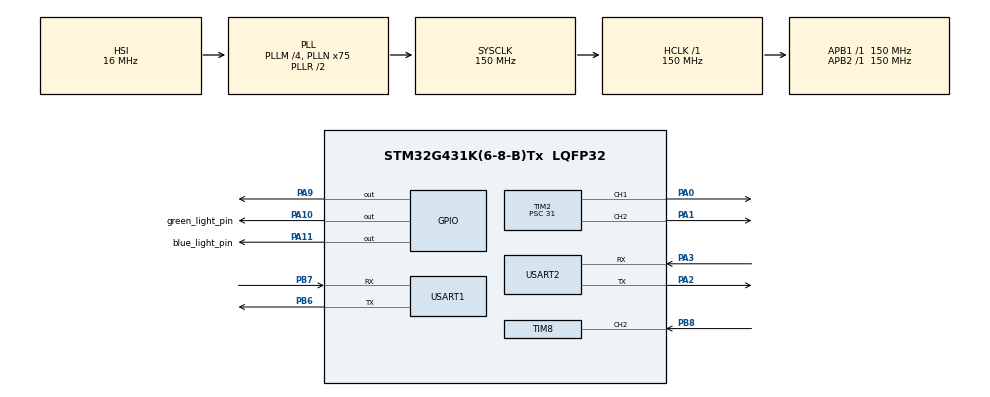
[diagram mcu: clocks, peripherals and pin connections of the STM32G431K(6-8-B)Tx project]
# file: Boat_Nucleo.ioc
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Dma.Request0=USART1_RX
Dma.Request1=USART1_TX
Dma.USART1_RX.0.Direction=DMA_PERIPH_TO_MEMORY
Dma.USART1_RX.0.EventEnable=DISABLE
Dma.USART1_RX.0.Instance=DMA1_Channel1
Dma.USART1_RX.0.MemDataAlignment=DMA_MDATAALIGN_BYTE
Dma.USART1_RX.0.MemInc=DMA_MINC_ENABLE
Dma.USART1_RX.0.Mode=DMA_NORMAL
Dma.USART1_RX.0.PeriphDataAlignment=DMA_PDATAALIGN_BYTE
Dma.USART1_RX.0.PeriphInc=DMA_PINC_DISABLE
Dma.USART1_RX.0.Polarity=HAL_DMAMUX_REQ_GEN_RISING
Dma.USART1_RX.0.Priority=DMA_PRIORITY_LOW
Dma.USART1_RX.0.RequestNumber=1
Dma.USART1_RX.0.SignalID=NONE
Dma.USART1_RX.0.SyncEnable=DISABLE
Dma.USART1_RX.0.SyncPolarity=HAL_DMAMUX_SYNC_NO_EVENT
Dma.USART1_RX.0.SyncRequestNumber=1
Dma.USART1_RX.0.SyncSignalID=NONE
Dma.USART1_TX.1.Direction=DMA_MEMORY_TO_PERIPH
Dma.USART1_TX.1.EventEnable=DISABLE
Dma.USART1_TX.1.Instance=DMA1_Channel2
Dma.USART1_TX.1.MemDataAlignment=DMA_MDATAALIGN_BYTE
Dma.USART1_TX.1.MemInc=DMA_MINC_ENABLE
Dma.USART1_TX.1.Mode=DMA_NORMAL
Dma.USART1_TX.1.PeriphDataAlignment=DMA_PDATAALIGN_BYTE
Dma.USART1_TX.1.PeriphInc=DMA_PINC_DISABLE
Dma.USART1_TX.1.Polarity=HAL_DMAMUX_REQ_GEN_RISING
Dma.USART1_TX.1.Priority=DMA_PRIORITY_LOW
Dma.USART1_TX.1.RequestNumber=1
Dma.USART1_TX.1.SignalID=NONE
Dma.USART1_TX.1.SyncEnable=DISABLE
Dma.USART1_TX.1.SyncPolarity=HAL_DMAMUX_SYNC_NO_EVENT
Dma.USART1_TX.1.SyncRequestNumber=1
Dma.USART1_TX.1.SyncSignalID=NONE
FREERTOS.Tasks01=idle_task,8,128,idle_task_update,Default,NULL,Dynamic,NULL,NULL;main_task,24,1024,main_task_thread,Default,NULL,Dynamic,NULL,NULL
FREERTOS.configCHECK_FOR_STACK_OVERFLOW=1
FREERTOS.configENABLE_FPU=1
FREERTOS.configIDLE_SHOULD_YIELD=1
FREERTOS.configTICK_RATE_HZ=250
FREERTOS.configTOTAL_HEAP_SIZE=8192
FREERTOS.configUSE_DAEMON_TASK_STARTUP_HOOK=0
FREERTOS.configUSE_IDLE_HOOK=0
FREERTOS.configUSE_MALLOC_FAILED_HOOK=0
FREERTOS.configUSE_PREEMPTION=0
FREERTOS.configUSE_TICKLESS_IDLE=0
FREERTOS.configUSE_TICK_HOOK=0
Mcu.Family=STM32G4
Mcu.Name=STM32G431K(6-8-B)Tx
Mcu.Package=LQFP32
NVIC.DMA1_Channel1_IRQn=true\:5\:0\:false\:false\:true\:true\:false\:true
NVIC.DMA1_Channel2_IRQn=true\:5\:0\:false\:false\:true\:true\:false\:true
NVIC.PriorityGroup=NVIC_PRIORITYGROUP_4
NVIC.TIM1_TRG_COM_TIM17_IRQn=true\:0\:0\:false\:false\:true\:false\:false\:true
NVIC.TimeBase=TIM1_TRG_COM_TIM17_IRQn
NVIC.TimeBaseIP=TIM17
PA0.Signal=S_TIM2_CH1
PA1.Signal=S_TIM2_CH2
PA10.GPIO_Label=green_light_pin
PA10.Signal=GPIO_Output
PA11.GPIO_Label=blue_light_pin
PA11.Signal=GPIO_Output
PA13.Mode=Serial_Wire
PA13.Signal=SYS_JTMS-SWDIO
PA14.Mode=Serial_Wire
PA14.Signal=SYS_JTCK-SWCLK
PA2.Mode=Asynchronous
PA2.Signal=USART2_TX
PA3.Mode=Asynchronous
PA3.Signal=USART2_RX
PA9.Signal=GPIO_Output
PB6.Mode=Asynchronous
PB6.Signal=USART1_TX
PB7.Mode=Asynchronous
PB7.Signal=USART1_RX
PB8-BOOT0.Signal=S_TIM8_CH2
ProjectManager.HeapSize=0x200
ProjectManager.StackSize=0x400
ProjectManager.TargetToolchain=STM32CubeIDE
RCC.ADC12Freq_Value=150000000
RCC.AHBFreq_Value=150000000
RCC.APB1Freq_Value=150000000
RCC.APB1TimFreq_Value=150000000
RCC.APB2Freq_Value=150000000
RCC.APB2TimFreq_Value=150000000
RCC.CortexFreq_Value=150000000
RCC.EXTERNAL_CLOCK_VALUE=12288000
RCC.HCLKFreq_Value=150000000
RCC.HSE_VALUE=8000000
RCC.HSI48_VALUE=48000000
RCC.HSI_VALUE=16000000
RCC.LSE_VALUE=32768
RCC.PLLM=RCC_PLLM_DIV4
RCC.PLLN=75
RCC.SYSCLKFreq_VALUE=150000000
RCC.SYSCLKSource=RCC_SYSCLKSOURCE_PLLCLK
RCC.USBFreq_Value=150000000
RCC.VCOOutputFreq_Value=300000000
SH.S_TIM2_CH1.0=TIM2_CH1,PWM Generation1 CH1
SH.S_TIM2_CH2.0=TIM2_CH2,PWM Generation2 CH2
SH.S_TIM8_CH2.0=TIM8_CH2,Input_Capture2_from_TI2
TIM2.AutoReloadPreload=TIM_AUTORELOAD_PRELOAD_ENABLE
TIM2.Channel-PWM\ Generation1\ CH1=TIM_CHANNEL_1
TIM2.Channel-PWM\ Generation2\ CH2=TIM_CHANNEL_2
TIM2.PeriodNoDither=100000
TIM2.Prescaler=31
TIM2.PulseNoDither_1=0
TIM2.PulseNoDither_2=0
TIM8.Channel-Input_Capture2_from_TI2=TIM_CHANNEL_2
USART1.VirtualMode-Asynchronous=VM_ASYNC
USART2.AutoBaudRateEnableParam=UART_ADVFEATURE_AUTOBAUDRATE_DISABLE
USART2.VirtualMode-Asynchronous=VM_ASYNC
VP_FREERTOS_VS_CMSIS_V2.Mode=CMSIS_V2
VP_SYS_VS_DBSignals.Mode=DisableDeadBatterySignals
VP_SYS_VS_tim17.Mode=TIM17
VP_TIM2_VS_ClockSourceINT.Mode=Internal
board=custom

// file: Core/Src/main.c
/* USER CODE BEGIN Header */
/**
  ******************************************************************************
  * @file           : main.c
  * @brief          : Main program body
  ******************************************************************************
  * @attention
  *
  * <h2><center>&copy; Copyright (c) 2020 STMicroelectronics.
  * All rights reserved.</center></h2>
  *
  * This software component is licensed by ST under Ultimate Liberty license
  * SLA0044, the "License"; You may not use this file except in compliance with
  * the License. You may obtain a copy of the License at:
  *                             www.st.com/SLA0044
  *
  ******************************************************************************
  */
/* USER CODE END Header */
#include "main.h"
#include "cmsis_os.h"

/* USER CODE BEGIN Includes */
#include "main_task.h"
/* USER CODE END Includes */

TIM_HandleTypeDef htim2;
TIM_HandleTypeDef htim8;

UART_HandleTypeDef huart1;
UART_HandleTypeDef huart2;
DMA_HandleTypeDef hdma_usart1_rx;
DMA_HandleTypeDef hdma_usart1_tx;

/* Definitions for idle_task */
osThreadId_t idle_taskHandle;
const osThreadAttr_t idle_task_attributes = {
  .name = "idle_task",
  .priority = (osPriority_t) osPriorityLow,
  .stack_size = 128 * 4
};
/* Definitions for main_task */
osThreadId_t main_taskHandle;
const osThreadAttr_t main_task_attributes = {
  .name = "main_task",
  .priority = (osPriority_t) osPriorityNormal,
  .stack_size = 1024 * 4
};

void SystemClock_Config(void);
static void MX_GPIO_Init(void);
static void MX_DMA_Init(void);
static void MX_TIM8_Init(void);
static void MX_USART2_UART_Init(void);
static void MX_TIM2_Init(void);
static void MX_USART1_UART_Init(void);
void idle_task_update(void *argument);
void main_task_thread(void *argument);

int main(void)
{

  /* MCU Configuration--------------------------------------------------------*/

  /* Reset of all peripherals, Initializes the Flash interface and the Systick. */
  HAL_Init();

  /* Configure the system clock */
  SystemClock_Config();

  /* Initialize all configured peripherals */
  MX_GPIO_Init();
  MX_DMA_Init();
  MX_TIM8_Init();
  MX_USART2_UART_Init();
  MX_TIM2_Init();
  MX_USART1_UART_Init();

  /* Init scheduler */
  osKernelInitialize();

  /* Create the thread(s) */
  /* creation of idle_task */
  idle_taskHandle = osThreadNew(idle_task_update, NULL, &idle_task_attributes);

  /* creation of main_task */
  main_taskHandle = osThreadNew(main_task_thread, NULL, &main_task_attributes);

  /* USER CODE BEGIN RTOS_THREADS */
  configASSERT(main_taskHandle != 0);
  /* add threads, ... */
  /* USER CODE END RTOS_THREADS */

  /* Start scheduler */
  osKernelStart();

  /* We should never get here as control is now taken by the scheduler */
  /* Infinite loop */
  while (1)
  {

  }
}

void SystemClock_Config(void)
{
  RCC_OscInitTypeDef RCC_OscInitStruct = {0};
  RCC_ClkInitTypeDef RCC_ClkInitStruct = {0};
  RCC_PeriphCLKInitTypeDef PeriphClkInit = {0};

  /** Configure the main internal regulator output voltage
  */
  HAL_PWREx_ControlVoltageScaling(PWR_REGULATOR_VOLTAGE_SCALE1);
  /** Initializes the RCC Oscillators according to the specified parameters
  * in the RCC_OscInitTypeDef structure.
  */
  RCC_OscInitStruct.OscillatorType = RCC_OSCILLATORTYPE_HSI;
  RCC_OscInitStruct.HSIState = RCC_HSI_ON;
  RCC_OscInitStruct.HSICalibrationValue = RCC_HSICALIBRATION_DEFAULT;
  RCC_OscInitStruct.PLL.PLLState = RCC_PLL_ON;
  RCC_OscInitStruct.PLL.PLLSource = RCC_PLLSOURCE_HSI;
  RCC_OscInitStruct.PLL.PLLM = RCC_PLLM_DIV4;
  RCC_OscInitStruct.PLL.PLLN = 75;
  RCC_OscInitStruct.PLL.PLLP = RCC_PLLP_DIV2;
  RCC_OscInitStruct.PLL.PLLQ = RCC_PLLQ_DIV2;
  RCC_OscInitStruct.PLL.PLLR = RCC_PLLR_DIV2;
  if (HAL_RCC_OscConfig(&RCC_OscInitStruct) != HAL_OK)
  {
    Error_Handler();
  }
  /** Initializes the CPU, AHB and APB buses clocks
  */
  RCC_ClkInitStruct.ClockType = RCC_CLOCKTYPE_HCLK|RCC_CLOCKTYPE_SYSCLK
                              |RCC_CLOCKTYPE_PCLK1|RCC_CLOCKTYPE_PCLK2;
  RCC_ClkInitStruct.SYSCLKSource = RCC_SYSCLKSOURCE_PLLCLK;
  RCC_ClkInitStruct.AHBCLKDivider = RCC_SYSCLK_DIV1;
  RCC_ClkInitStruct.APB1CLKDivider = RCC_HCLK_DIV1;
  RCC_ClkInitStruct.APB2CLKDivider = RCC_HCLK_DIV1;

  if (HAL_RCC_ClockConfig(&RCC_ClkInitStruct, FLASH_LATENCY_4) != HAL_OK)
  {
    Error_Handler();
  }
  /** Initializes the peripherals clocks
  */
  PeriphClkInit.PeriphClockSelection = RCC_PERIPHCLK_USART1|RCC_PERIPHCLK_USART2;
  PeriphClkInit.Usart1ClockSelection = RCC_USART1CLKSOURCE_PCLK2;
  PeriphClkInit.Usart2ClockSelection = RCC_USART2CLKSOURCE_PCLK1;
  if (HAL_RCCEx_PeriphCLKConfig(&PeriphClkInit) != HAL_OK)
  {
    Error_Handler();
  }
}

static void MX_TIM2_Init(void)
{

  TIM_ClockConfigTypeDef sClockSourceConfig = {0};
  TIM_MasterConfigTypeDef sMasterConfig = {0};
  TIM_OC_InitTypeDef sConfigOC = {0};

  htim2.Instance = TIM2;
  htim2.Init.Prescaler = 31;
  htim2.Init.CounterMode = TIM_COUNTERMODE_UP;
  htim2.Init.Period = 100000;
  htim2.Init.ClockDivision = TIM_CLOCKDIVISION_DIV1;
  htim2.Init.AutoReloadPreload = TIM_AUTORELOAD_PRELOAD_ENABLE;
  if (HAL_TIM_Base_Init(&htim2) != HAL_OK)
  {
    Error_Handler();
  }
  sClockSourceConfig.ClockSource = TIM_CLOCKSOURCE_INTERNAL;
  if (HAL_TIM_ConfigClockSource(&htim2, &sClockSourceConfig) != HAL_OK)
  {
    Error_Handler();
  }
  if (HAL_TIM_PWM_Init(&htim2) != HAL_OK)
  {
    Error_Handler();
  }
  sMasterConfig.MasterOutputTrigger = TIM_TRGO_RESET;
  sMasterConfig.MasterSlaveMode = TIM_MASTERSLAVEMODE_DISABLE;
  if (HAL_TIMEx_MasterConfigSynchronization(&htim2, &sMasterConfig) != HAL_OK)
  {
    Error_Handler();
  }
  sConfigOC.OCMode = TIM_OCMODE_PWM1;
  sConfigOC.Pulse = 0;
  sConfigOC.OCPolarity = TIM_OCPOLARITY_HIGH;
  sConfigOC.OCFastMode = TIM_OCFAST_DISABLE;
  if (HAL_TIM_PWM_ConfigChannel(&htim2, &sConfigOC, TIM_CHANNEL_1) != HAL_OK)
  {
    Error_Handler();
  }
  sConfigOC.Pulse = 0;
  if (HAL_TIM_PWM_ConfigChannel(&htim2, &sConfigOC, TIM_CHANNEL_2) != HAL_OK)
  {
    Error_Handler();
  }
  HAL_TIM_MspPostInit(&htim2);

}

static void MX_TIM8_Init(void)
{

  TIM_MasterConfigTypeDef sMasterConfig = {0};
  TIM_IC_InitTypeDef sConfigIC = {0};
  TIM_BreakDeadTimeConfigTypeDef sBreakDeadTimeConfig = {0};

  htim8.Instance = TIM8;
  htim8.Init.Prescaler = 0;
  htim8.Init.CounterMode = TIM_COUNTERMODE_UP;
  htim8.Init.Period = 65535;
  htim8.Init.ClockDivision = TIM_CLOCKDIVISION_DIV1;
  htim8.Init.RepetitionCounter = 0;
  htim8.Init.AutoReloadPreload = TIM_AUTORELOAD_PRELOAD_DISABLE;
  if (HAL_TIM_IC_Init(&htim8) != HAL_OK)
  {
    Error_Handler();
  }
  sMasterConfig.MasterOutputTrigger = TIM_TRGO_RESET;
  sMasterConfig.MasterOutputTrigger2 = TIM_TRGO2_RESET;
  sMasterConfig.MasterSlaveMode = TIM_MASTERSLAVEMODE_DISABLE;
  if (HAL_TIMEx_MasterConfigSynchronization(&htim8, &sMasterConfig) != HAL_OK)
  {
    Error_Handler();
  }
  sConfigIC.ICPolarity = TIM_INPUTCHANNELPOLARITY_RISING;
  sConfigIC.ICSelection = TIM_ICSELECTION_DIRECTTI;
  sConfigIC.ICPrescaler = TIM_ICPSC_DIV1;
  sConfigIC.ICFilter = 0;
  if (HAL_TIM_IC_ConfigChannel(&htim8, &sConfigIC, TIM_CHANNEL_2) != HAL_OK)
  {
    Error_Handler();
  }
  sBreakDeadTimeConfig.BreakAFMode = TIM_BREAK_AFMODE_INPUT;
  sBreakDeadTimeConfig.Break2AFMode = TIM_BREAK_AFMODE_INPUT;
  if (HAL_TIMEx_ConfigBreakDeadTime(&htim8, &sBreakDeadTimeConfig) != HAL_OK)
  {
    Error_Handler();
  }

}

static void MX_USART1_UART_Init(void)
{

  huart1.Instance = USART1;
  huart1.Init.BaudRate = 115200;
  huart1.Init.WordLength = UART_WORDLENGTH_8B;
  huart1.Init.StopBits = UART_STOPBITS_1;
  huart1.Init.Parity = UART_PARITY_NONE;
  huart1.Init.Mode = UART_MODE_TX_RX;
  huart1.Init.HwFlowCtl = UART_HWCONTROL_NONE;
  huart1.Init.OverSampling = UART_OVERSAMPLING_16;
  huart1.Init.OneBitSampling = UART_ONE_BIT_SAMPLE_DISABLE;
  huart1.Init.ClockPrescaler = UART_PRESCALER_DIV1;
  huart1.AdvancedInit.AdvFeatureInit = UART_ADVFEATURE_NO_INIT;
  if (HAL_UART_Init(&huart1) != HAL_OK)
  {
    Error_Handler();
  }
  if (HAL_UARTEx_SetTxFifoThreshold(&huart1, UART_TXFIFO_THRESHOLD_1_8) != HAL_OK)
  {
    Error_Handler();
  }
  if (HAL_UARTEx_SetRxFifoThreshold(&huart1, UART_RXFIFO_THRESHOLD_1_8) != HAL_OK)
  {
    Error_Handler();
  }
  if (HAL_UARTEx_DisableFifoMode(&huart1) != HAL_OK)
  {
    Error_Handler();
  }

}

static void MX_USART2_UART_Init(void)
{

  huart2.Instance = USART2;
  huart2.Init.BaudRate = 115200;
  huart2.Init.WordLength = UART_WORDLENGTH_8B;
  huart2.Init.StopBits = UART_STOPBITS_1;
  huart2.Init.Parity = UART_PARITY_NONE;
  huart2.Init.Mode = UART_MODE_TX_RX;
  huart2.Init.HwFlowCtl = UART_HWCONTROL_NONE;
  huart2.Init.OverSampling = UART_OVERSAMPLING_16;
  huart2.Init.OneBitSampling = UART_ONE_BIT_SAMPLE_DISABLE;
  huart2.Init.ClockPrescaler = UART_PRESCALER_DIV1;
  huart2.AdvancedInit.AdvFeatureInit = UART_ADVFEATURE_NO_INIT;
  if (HAL_UART_Init(&huart2) != HAL_OK)
  {
    Error_Handler();
  }
  if (HAL_UARTEx_SetTxFifoThreshold(&huart2, UART_TXFIFO_THRESHOLD_1_8) != HAL_OK)
  {
    Error_Handler();
  }
  if (HAL_UARTEx_SetRxFifoThreshold(&huart2, UART_RXFIFO_THRESHOLD_1_8) != HAL_OK)
  {
    Error_Handler();
  }
  if (HAL_UARTEx_DisableFifoMode(&huart2) != HAL_OK)
  {
    Error_Handler();
  }

}

static void MX_DMA_Init(void)
{

  /* DMA controller clock enable */
  __HAL_RCC_DMAMUX1_CLK_ENABLE();
  __HAL_RCC_DMA1_CLK_ENABLE();

  /* DMA interrupt init */
  /* DMA1_Channel1_IRQn interrupt configuration */
  HAL_NVIC_SetPriority(DMA1_Channel1_IRQn, 5, 0);
  HAL_NVIC_EnableIRQ(DMA1_Channel1_IRQn);
  /* DMA1_Channel2_IRQn interrupt configuration */
  HAL_NVIC_SetPriority(DMA1_Channel2_IRQn, 5, 0);
  HAL_NVIC_EnableIRQ(DMA1_Channel2_IRQn);

}

static void MX_GPIO_Init(void)
{
  GPIO_InitTypeDef GPIO_InitStruct = {0};

  /* GPIO Ports Clock Enable */
  __HAL_RCC_GPIOA_CLK_ENABLE();
  __HAL_RCC_GPIOB_CLK_ENABLE();

  /*Configure GPIO pin Output Level */
  HAL_GPIO_WritePin(GPIOA, GPIO_PIN_9|green_light_pin_Pin|blue_light_pin_Pin, GPIO_PIN_RESET);

  /*Configure GPIO pins : PA9 green_light_pin_Pin blue_light_pin_Pin */
  GPIO_InitStruct.Pin = GPIO_PIN_9|green_light_pin_Pin|blue_light_pin_Pin;
  GPIO_InitStruct.Mode = GPIO_MODE_OUTPUT_PP;
  GPIO_InitStruct.Pull = GPIO_NOPULL;
  GPIO_InitStruct.Speed = GPIO_SPEED_FREQ_LOW;
  HAL_GPIO_Init(GPIOA, &GPIO_InitStruct);

}

void idle_task_update(void *argument)
{
  /* USER CODE BEGIN 5 */
  /* Infinite loop */
  for(;;)
  {
    osDelay(10000);
  }
  /* USER CODE END 5 */
}

void main_task_thread(void *argument)
{
  /* USER CODE BEGIN main_task_thread */
  main_task_update(argument);
  /* USER CODE END main_task_thread */
}

 /**
  * @brief  Period elapsed callback in non blocking mode
  * @note   This function is called  when TIM17 interrupt took place, inside
  * HAL_TIM_IRQHandler(). It makes a direct call to HAL_IncTick() to increment
  * a global variable "uwTick" used as application time base.
  * @param  htim : TIM handle
  * @retval None
  */
void HAL_TIM_PeriodElapsedCallback(TIM_HandleTypeDef *htim)
{
  if (htim->Instance == TIM17) {
    HAL_IncTick();
  }
}

void Error_Handler(void)
{
  __disable_irq();
  while (1)
  {
  }
}

/************************ (C) COPYRIGHT STMicroelectronics *****END OF FILE****/

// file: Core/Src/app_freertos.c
/* USER CODE BEGIN Header */
/**
  ******************************************************************************
  * File Name          : app_freertos.c
  * Description        : Code for freertos applications
  ******************************************************************************
  * @attention
  *
  * <h2><center>&copy; Copyright (c) 2020 STMicroelectronics.
  * All rights reserved.</center></h2>
  *
  * This software component is licensed by ST under Ultimate Liberty license
  * SLA0044, the "License"; You may not use this file except in compliance with
  * the License. You may obtain a copy of the License at:
  *                             www.st.com/SLA0044
  *
  ******************************************************************************
  */
/* USER CODE END Header */

#include "FreeRTOS.h"
#include "task.h"
#include "main.h"

/* Hook prototypes */
void vApplicationStackOverflowHook(xTaskHandle xTask, signed char *pcTaskName);

/* USER CODE BEGIN 4 */
void vApplicationStackOverflowHook(xTaskHandle xTask, signed char *pcTaskName)
{
   /* Run time stack overflow checking is performed if
   configCHECK_FOR_STACK_OVERFLOW is defined to 1 or 2. This hook function is
   called if a stack overflow is detected. */
}
/* USER CODE END 4 */

/************************ (C) COPYRIGHT STMicroelectronics *****END OF FILE****/
